# cslr_lcdc_001 register map
Vendor: Texas Instruments
Peripheral module from a debugger description file (folder C5505).
Address unit: 16 bits
Registers are 16-bit, read-write, reset 0x0 unless marked. A register's access mark holds for its fields unless they carry their own. Offsets are as the file gives them; lines under a group give offsets from that group; [hi:lo] are bit positions; {n}, {i} and the like mark numbered series; 'fields as' and 'values as' point back to an identical list; <NAME> marks a mode.

## LCDC — LCD Controller
0x00 LCDREVMIN reset 0x1000 — LCD Minor Revision Register
  [15:0] REVMIN — Minor Revision
0x02 LCDREVMAJ reset not defined — LCD Major Revision Register
  [15:0] REVMAJ — Major Revision
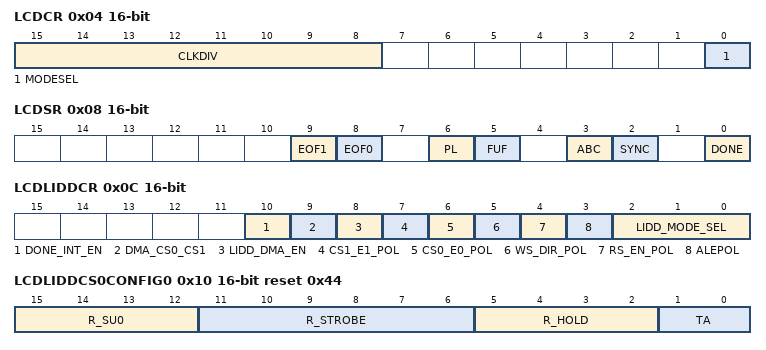
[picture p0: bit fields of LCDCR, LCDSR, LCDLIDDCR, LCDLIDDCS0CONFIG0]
0x04 LCDCR access not given — LCD Control Register
  [15:8] CLKDIV rw — Clock Divisor Value (from 0 255) is used to specify the frequency of the pixel clock (in Raster mode) or MCLK (in LIDD mode) based on the lcd_clk frequency. Pixel clock frequency can range from lcd_clk/2 to lcd_clk/255 (clkdiv=0 or clkdiv=1 are N/A); MCLK can vary from lcd_clk to lcd_clk/255 (clkdiv=0 or clkdiv=1 sets MCLK=lcd_clk)
  [0] MODESEL rw — LCD Mode Select
    0=LIDD (LCD Controller in LIDD mode); 1=RASTER (LCD Controller in Raster mode)
0x08 LCDSR access not given — LCD Status Register
  [9] EOF1 rw — End of Frame 1 0: no end of frame 1 detected 1: end of frame 1 detected
    0=CLEAR (End of frame 1 not detected); 1=SET (end of frame 1 detected)
  [8] EOF0 rw — End of Frame 0 0: no end of frame 0 detected 1: end of frame 0 detected
    0=CLEAR (End of frame 0 not detected); 1=SET (end of frame 0 detected)
  [6] PL rw — Loaded Palette 0: The palette is not loaded 1: The palette is loaded
    0=CLEAR (Palette not loaded); 1=SET (Palette loaded)
  [5] FUF rw — FIFO Underflow Status 0: FIFO has not underrun 1: LCD dither logic not supplying data to FIFO at a sufficient rate, FIFO has completely emptied and data pin driver logic has attempted to take added data from FIFO
    0=CLEAR (No FIFO underrun); 1=SET (FIFO completely empty and data pin attempted to take added data from FIFO)
  [3] ABC rw — AC Bias Count Status 0: AC bias transition counter has not decremented to zero 1: AC bias transition counter has decremented to zero, indicating that the lcd_ac_o line has transitioned the number of times which is specified by the acbi control bit-field. Counter is reloaded with value in acbi but is disabled until the user clears ABC
    0=CLEAR (AC bias transition counter not zero); 1=SET (AC bias transition counter decremented to zero)
  [2] SYNC rw — Sync Lost 0: normal 1: Frame Synchronization Lost has occurred
    0=CLEAR (Normal operation); 1=SET (Lost Frame Sync)
  [0] DONE rw — Raster or LIDD Frame Done (shared; depends on whether Raster or LIDD mode enabled) 0: Raster or DMA-to-LIDD engine is enabled 1: Raster or DMA-to-LIDD disabled and the active frame has just completed
    0=CLEAR (Raster engine enabled); 1=SET (Raster engine disabled)
0x0C LCDLIDDCR access not given — LCD LIDD Control Register
  [10] DONE_INT_EN rw — LIDD Frame Done Interrupt Enable 0: Disable LIDD Frame Done interrupt 1: Enable LIDD Frame Done interrupt (seen on LCD Status Reg bit 0)
    0=DISABLE (Disable LIDD Frame Done interrupt); 1=ENABLE (Enable LIDD Frame Done interrupt (seen on LCD Status Reg bit 0))
  [9] DMA_CS0_CS1 rw — CS0/CS1 Select for LIDD DMA writes 0: DMA writes to LIDD CS0 1: DMA writes to LIDD CS1
    0=CS0 (DMA writes to LIDD CS0); 1=CS1 (DMA writes to LIDD CS1)
  [8] LIDD_DMA_EN rw — LIDD DMA Enable 0: Deactivate DMA control of LIDD interface; DMA control is released upon completion of transfer of the currentframe of data (LIDD Frame Done) after this bit is cleared. The MPU has direct read/write access to the panel in this mode 1: Activate DMA to drive LIDD interface to support streaming data to smart panels. The MPU cannot access the panel directly in this mode
    0=DISABLE (Disable DMA control of LIDD); 1=ENABLE (Enable DMA to drive LIDD interface to support streaming data to smart panels.)
  [7] CS1_E1_POL rw — Chip Select 1/Enable 1 (Secondary) Polarity Control 0: Do Not Invert Chip Select 1/Enable 1 1: Invert Chip Select 1/Enable 1 Chip Select 1 is active low by default; Enable 1 is active high by default
    0=NORMAL (No Invert for CS1/EN1); 1=INVERT (Inverts CS1/EN1)
  [6] CS0_E0_POL rw — Chip Select 0/Enable 0 (Primary) Polarity Control 0: Do Not Invert Chip Select 0/Enable 0 1: Invert Chip Select 0/Enable 0 Chip Select 0 is active low by default; Enable 0 is active high by default
    0=NORMAL (No Invert for CS0/EN0); 1=INVERT (Inverts CS0/EN0)
  [5] WS_DIR_POL rw — Write Strobe/Direction Polarity Control 0: Do Not Invert Write Strobe/Direction 1: Invert Write Strobe/Direction Write Strobe/Direction is active low/write low by default
    0=NORMAL (No Invert for WS/Dir); 1=INVERT (Invert WS/Dir)
  [4] RS_EN_POL rw — Read Strobe/Enable Polarity Control 0: Do Not Invert Read Strobe/Enable 1: Invert Read Strobe/Enable Read Strobe is active low by default; Enable is active high by default
    0=NORMAL (No invert for RS/En); 1=INVERT (Invert RS/En)
  [3] ALEPOL rw — Address Latch Enable (ALE) Polarity Control 0: Do Not Invert ALE 1: Invert ALE ALE is active low by default
    0=NORMAL (No invert for ALE); 1=INVERT (Invert ALE)
  [2:0] LIDD_MODE_SEL rw — LIDD Mode Select. Selects type of LCD display interface for the LIDD to drive LIDD Mode Select defines the function of LCD external pins as follows ------------------------------------------------------------------------------------ PIN 000b 001b 010b 011b 100b ------------------------------------------------------------------------------------ lcd_cp En En Rs Rs N/A lcd_lp Dir Dir Ws Ws Dir lcd_fp Ale Ale Ale Ale Ale lcd_ac Cs0 Cs0 Cs0 Cs0 E0 lcd_mclk Mclk Cs1 Mclk Cs1 E1
    0=SYNC_MPU68; 1=ASYNC_MPU68; 2=SYNC_MPU80; 3=ASYNC_MPU80; 4=HITACHI (Hitachi (Async))
0x10 LCDLIDDCS0CONFIG0 reset 0x44 — LCD LIDD CS0 Configuration Register 0
  [15:12] R_SU0 — Read Strobe Set-Up cycles (lower 4 bits upper bit is in LIDD CSO config reg 1 at bit-0) Field value defines number of memclk cycles after Data Bus/Pad Output Enable, ALE, Direction bit and Chip Select 0 have been set-up before the Read Strobe is asserted when performing a read access
  [11:6] R_STROBE — Read Strobe Duration cycles Field value defines number of memclk cycles for which the Read Strobe is held active when performing a read access
  [5:2] R_HOLD — Read Strobe Hold cycles Field value defines number of memclk cycles for which Data Bus/Pad Output Enable, ALE, Direction bit and Chip Select 0 are held after the Read Strobe is deasserted when performing a read access
  [1:0] TA — Field value defines number of memclk cycles between the end of one CS0 device access and the start of another CS0 device access unless the two accesses are both reads, in which case this delay is not incurred
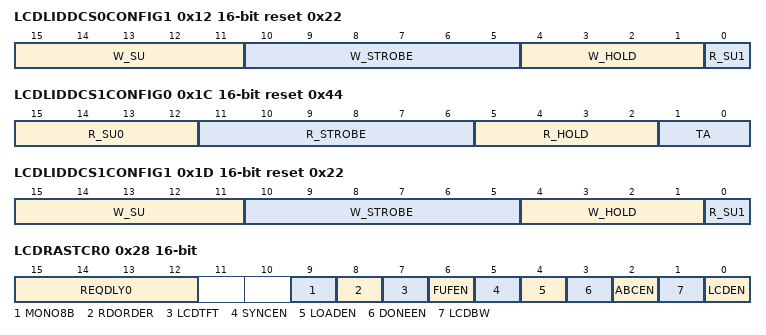
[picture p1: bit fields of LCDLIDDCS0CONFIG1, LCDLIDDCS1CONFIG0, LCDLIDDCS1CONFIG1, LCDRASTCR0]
0x12 LCDLIDDCS0CONFIG1 reset 0x22 — LCD LIDD CS0 Configuration Register 1
  [15:11] W_SU — Write Strobe Set-Up cycles Field value defines number of memclk cycles after Data Bus/Pad Output Enable, ALE, Direction bit and Chip Select 0 have been set-up before the Write Strobe is asserted when performing a write access
  [10:5] W_STROBE — Write Strobe Duration cycles Field value defines number of memclk cycles for which the Write Strobe is held active when performing a write access
  [4:1] W_HOLD — Write Strobe Hold cycles Field value defines number of memclk cycles for which Data Bus/Pad Output Enable, ALE, Direction bit and Chip Select 0 are held after the Write Strobe is deasserted when performing a write access
  [0] R_SU1 — Most Significant Bit for Read Strobe Set-Up cycles (upper bit. The lower 4 bits are located in LIDD CSO confir reg 0) Field value defines number of memclk cycles after Data Bus/Pad Output Enable, ALE, Direction bit and Chip Select 0 have been set-up before the Read Strobe is asserted when performing a read access
0x14 LCDLIDDCS0ADDR — LCD LIDD CS0 Address Read/Write Register
  [15:0] ADR_INDX — Peripheral Device Address/Index value On writes this field is loaded into the CS0 peripheral device s address generator On reads this field contains the CS0 peripheral device s status
0x18 LCDLIDDCS0DATA — LCD LIDD CS0 Data Read/Write Register
  [15:0] DATA — Peripheral Device Data value On writes this field is loaded into the CS0 peripheral device On reads this field contains the CS0 peripheral device s data
0x1C LCDLIDDCS1CONFIG0 reset 0x44 — LCD LIDD CS1 Configuration Register 0
  fields as LCDLIDDCS0CONFIG0
0x1D LCDLIDDCS1CONFIG1 reset 0x22 — LCD LIDD CS1 Configuration Register 1
  [15:11] W_SU — Write Strobe Set-Up cycles Field value defines number of memclk cycles after Data Bus/Pad Output Enable, ALE, Direction bit and Chip Select 0 have been set-up before the Write Strobe is asserted when performing a write access
  [10:5] W_STROBE — Write Strobe Duration cycles Field value defines number of memclk cycles for which the Write Strobe is held active when performing a write access
  [4:1] W_HOLD — Write Strobe Hold cycles Field value defines number of memclk cycles for which Data Bus/Pad Output Enable, ALE, Direction bit and Chip Select 0 are held after the Write Strobe is deasserted when performing a write access
  [0] R_SU1 — Read Strobe Set-Up cycles (upper bit. The lower 4 bits are located in LIDD CSO confir reg 0) Field value defines number of memclk cycles after Data Bus/Pad Output Enable, ALE, Direction bit and Chip Select 0 have been set-up before the Read Strobe is asserted when performing a read access
0x20 LCDLIDDCS1ADDR — LCD LIDD CS1 Address Read/Write Register
  fields as LCDLIDDCS0ADDR
0x24 LCDLIDDCS1DATA — LCD LIDD CS1 Data Read/Write Register
  fields as LCDLIDDCS0DATA
0x28 LCDRASTCR0 access not given — LCD Raster Control Register 0
  [15:12] REQDLY0 rw — FIFO DMA Request Delay Encoded value (0-255) used to specify the number of memory controller clocks the input FIFO DMA request should be disabled. The clock count starts after 16 words read in the input FIFO. Programming reqdly=00h disables this function
  [9] MONO8B rw — Mono 8 Bit Mode 0: lcd_pixel_o[3:0] is used to output four pixel values to the panel each pixel clock transition 1: lcd_pixel_o[7:0] is used to output eight pixel values to the panel each pixel clock transition This bit is ignored in all other modes
    0=FOUR (Each LCD pixel has 4 values); 1=EIGHT (Each LCD pixel has 8 values)
  [8] RDORDER rw — Raster Data Order Select 0: Frame buffer data is ordered from least-to-most significant bit/nibble/byte/halfword 1: Frame buffer data is ordered from most-to-least significant bit/nibble/byte/halfword
    0=CLEAR (Frame buffer data is ordered from Least to Most significant); 1=SET (Frame buffer data is ordered from Most to Least significant)
  [7] LCDTFT rw — LCD TFT 0: Passive or STN display operation enabled, dither logic is enabled 1: Active or TFT display operation enabled, external palette and DAC required, dither logic bypassed, pin timing changes to support continuous pixel clock, output enable, vsync and hsync
    0=PASSIVE (Passive display operation enabled); 1=ACTIVE (Active display operation enabled)
  [6] FUFEN rw — FIFO Underflow interrupt enable
    0=DISABLE (FIFO Interrupt Disabled); 1=ENABLE (FIFO Interrupt enabled)
  [5] SYNCEN rw — Sync Lost interrupt enable
    0=DISABLE (Sync Lost interrupt disabled); 1=ENABLE (Sync Lost interrupt enabled)
  [4] LOADEN rw — Palette Load interrupt enable
    0=DISABLE (Palette load interrupt disabled); 1=ENABLE (Palette load interrupt enabled)
  [3] DONEEN rw — Frame Done interrupt enable
    0=DISABLE (Frame done interrupt disabled); 1=ENABLE (Frame done interrupt enabled)
  [2] ABCEN rw — AC Bias Count interrupt enable
    0=DISABLE (AC bias count interrupt disabled); 1=ENABLE (AC bias count interrupt enabled)
  [1] LCDBW rw — LCD Monochrome 0: Color operation enabled 1: Monochrome operation enabled
    0=COLOR (Color enabled); 1=MONO (Monochrome enabled)
  [0] LCDEN rw — LCD Controller Enable
    0=DISABLE (LCD controller disabled); 1=ENABLE (LCD controller enabled)
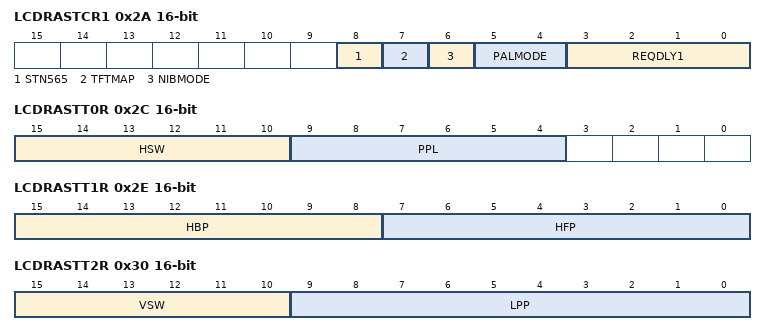
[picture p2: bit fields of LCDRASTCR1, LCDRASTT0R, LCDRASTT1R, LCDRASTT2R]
0x2A LCDRASTCR1 access not given — LCD Raster Control Register 1
  [8] STN565 rw — 12 BPP (5-6-5) mode 0: off 1: on (16 bit data in frame buffer, but only 12 bits are dithered and sent out)
    0=OFF (12 BPP mode off); 1=ON (12 BPP mode on)
  [7] TFTMAP rw — TFT Alternate Signal Mapping 0: output pixel data for 1, 2, 4, and 8 bpp modes will be right aligned on lcd_pins (11:0) 1: output pixel data for 1, 2, 4, and 8 bpp will be converted to 5,6,5 format and use pins (15:0) R3 R2 R1 R0 R3 G3 G2 G1 G0 G3 G2 B3 B2 B1 B0 B3
    0=CLEAR (output pixel data for 1, 2, 4, and 8 bpp modes will be right aligned on lcd_pins (11:0)); 1=SET (output pixel data for 1, 2, 4, and 8 bpp will be converted to 5,6,5 format and use pins (15:0) R3 R2 R1 R0 R3 G3 G2 G1 G0 G3 G2 B3 B2 B1 B0 B3)
  [6] NIBMODE rw — Nibble Mode 0: Nibble mode is disabled 1: Nibble mode is enabled
    0=DISABLE (Nibble mode disabled); 1=ENABLE (Nibble mode enabled)
  [5:4] PALMODE rw — Palette Loading Mode 00: Palette and data loading ( reset value) 01: Palette loading 10: Data loading
    0=DEFAULT (Palette and data loading (default)); 1=PALETTE (Palette loading); 2=DATA (Data loading)
  [3:0] REQDLY1 rw — FIFO DMA Request Delay Encoded value (0-255) used to specify the number of memory controller clocks the input FIFO DMA request should be disabled. The clock count starts after 16 words read in the input FIFO. Programming reqdly=00h disables this function
0x2C LCDRASTT0R access not given — LCD Raster Timing 0 Register
  [15:10] HSW rw — Horizontal Sync Pulse Width Encoded value (from 1 64) is used to specify number of pixel clock periods to pulse the line clock at the end of each line (program to value minus one). Note that pixel clock is held in its inactive state during the generation of the line clock in passive display mode and is permitted to transition in active display mode
  [9:4] PPL rw — Pixels-per-line Encoded value (from 1 1024) is used to specify number of pixels contained within each line on the LCD display (program to value minus one)
0x2E LCDRASTT1R — LCD Raster Timing 1 Register
  [15:8] HBP — Horizontal Back Porch Encoded value (from 1 256) is used to specify number of pixel clock periods to add to the beginning of a line transmission before the first set of pixels is output to the display (program to value minus one). Note that pixel clock is held in its inactive state during the beginning of line wait period in passive display mode and is permitted to transition in active display mode
  [7:0] HFP — Horizontal Front Porch Encoded value (from 1 256) is used to specify number of pixel clock periods to add to the end of a line transmission before line clock is asserted (program to value minus one). Note that pixel clock is held in its inactive state during the end of line wait period in passive display mode and is permitted to transition in active display mode
0x30 LCDRASTT2R — LCD Raster Timing 2 Register
  [15:10] VSW — Vertical Sync Pulse Width In active mode (lcdtft=1), encoded value (from 1 64) used to specify number of line clock periods to pulse the lcd_fp pin at the end of each frame after the end of frame wait (vfp) period elapses. Frame clock used as VSYNC signal in active mode In passive mode (lcdtft=0), encoded value (from 1 64) used to specify number of extra line clock periods to insert after the vertical front porch (vfp) period has elapsed. Note that the width of lcd_fp is not effected by vsw in passive mode, and that line clock transitions during the insertionof the extra line clock periods (program to value minus one)
  [9:0] LPP — Pixels-per-line Encoded value (from 1 1024) used to specify number of lines per panel. It represents the total number of lines on the LCD (program to value minus one)
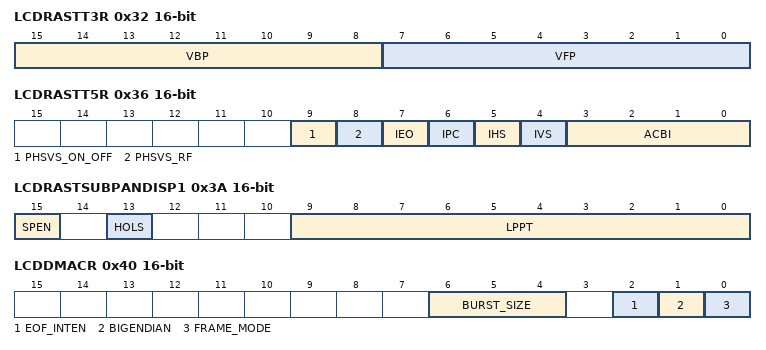
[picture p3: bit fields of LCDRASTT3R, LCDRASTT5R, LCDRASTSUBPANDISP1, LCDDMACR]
0x32 LCDRASTT3R — LCD Raster Timing 3 Register
  [15:8] VBP — Vertical Back Porch Value (from 0 255) used to specify number of line clock periods to add to the beginning of a frame before the first set of pixels is output to the display. Note that line clock transitions during the insertion of the extra line clock periods
  [7:0] VFP — Vertical Front Porch Value (from 0 255) used to specify number of line clock periods to add to the end of each frame. Note that the line clock transitions during the insertion of the extra line clock periods
0x34 LCDRASTT4R access not given — LCD Raster Timing 4 Register
  [15:8] ACB rw — AC Bias Pin Frequency Value (from 0 255) used to specify the number of line clocks to count before transitioning the AC Bias pin. This pin is used to periodically invert the polarity of the power supply to prevent DC charge build-up within the display. acb: Number of line clocks/toggle of the lcd_ac pin
0x36 LCDRASTT5R access not given — LCD Raster Timing 5 Register
  [9] PHSVS_ON_OFF rw — Hsync/Vsync Pixel Clock Control On/Off Should be ON only when in TFT mode 0: lcd_lp and lcd_fp are driven on opposite edges of pixel clock than the lcd_pixel_o 1: lcd_lp and lcd_fp are driven according to bit 24
    0=CLEAR (lcd_lp and lcd_fp are driven on opposite edges of pixel clock than the lcd_pixel_o); 1=SET (lcd_lp and lcd_fp are driven according to bit 24)
  [8] PHSVS_RF rw — Program Hsync/Vsync Rise or Fall 0: lcd_lp and lcd_fp are driven on rising edge of pixel clock. (bit 25 must be set to 1) 1: lcd_lp and lcd_fp are driven on falling edge of pixel clock. (bit 25 must be set to 1)
    0=RISING (lcd_lp and lcd_fp are driven on rising edge of pixel clock. (bit 25 must be set to 1)); 1=FALLING (lcd_lp and lcd_fp are driven on falling edge of pixel clock. (bit 25 must be set to 1))
  [7] IEO rw — Invert Output Enable 0: lcd_ac pin is active high in active display mode 1: lcd_ac pin is active low in active display mode Active display mode: data driven out to the LCD s data lines on programmed pixel clock edge when AC-bias is active. Note that IEO is ignored in passive display mode
    0=HIGH (LCD_AC pin is active high in Active Display mode); 1=LOW (LCD_AC pin is active low in Active Display mode)
  [6] IPC rw — Invert Pixel Clock 0: Data is driven on the LCD s data lines on the rising edge of lcd_cp 1: Data is driven on the LCD s data lines on the falling edge of lcd_cp
    0=RISING (Data driven on rising edge); 1=FALLING (Data driven on Falling edge)
  [5] IHS rw — Invert Hsync 0: lcd_lp pin is active high and inactive low 1: lcd_lp pin is active low and inactive high Active and passive mode: horizontal sync pulse/line clock active between lines, after end of line wait period
    0=CLEAR (lcd_lp pin is active high and inactive low); 1=SET (lcd_lp pin is active low and inactive high)
  [4] IVS rw — Invert Vsync 0: lcd_fp pin is active high and inactive low 1: lcd_fp pin is active low and inactive high Active mode: vertical sync pulse active between frames, after end of frame wait period Passive mode: frame clock active during first line of each frame
    0=CLEAR (lcd_fp pin is active high and inactive low); 1=SET (lcd_fp pin is active low and inactive high)
  [3:0] ACBI rw — AC Bias Pin Transitions per Interrupt Value (from 0 to 255) used to specify the number of AC Bias pin transitions to count before setting the line count status (lcs) bit, signaling an interrupt request. Counter is frozen when lcs is set and is restarted when lcs is cleared by software. This function is disabled when acbi = 0x0000
0x38 LCDRASTSUBPANDISP0 access not given — LCD Raster Sub-panel Display Register 0
  [15:4] DPD rw — Default Pixel Data DPD defines the default value of the pixel data sent to the panel for the lines until LPPT is reached or after passing the LPPT
0x3A LCDRASTSUBPANDISP1 access not given — LCD Raster Sub-panel Display Register 1
  [15] SPEN rw — Sub panel Enable 0: function disabled 1: sub-panel function mode enabled
    0=DISABLE (Sub panel function disabled); 1=ENABLE (Sub panel function enabled)
  [13] HOLS rw — High or Low Signal The field indicates the position of sub-panel compared to the LPPT value
    0=LOW (subpanel below LPPT value); 1=HIGH (subpanel above LPPT value)
  [9:0] LPPT rw — Line Per Panel Threshold This field defines the number of lines to be refreshed (1 1024)
0x40 LCDDMACR access not given — LCD DMA Control Register
  [6:4] BURST_SIZE rw — Burst Size setting for DMA transfers (all DMA transfers are 32 bits wide)
    0=BSIZE1 (burst size of 1); 1=BSIZE2 (burst size of 2); 2=BSIZE4 (burst size of 4); 3=BSIZE8 (burst size of 8); 4=BSIZE16 (burst size of 16)
  [2] EOF_INTEN rw — End of Frame interrupt enable Setting this bit allows the End of Frame 0 or 1 Status bits in the LCD Status Register to trigger an interrupt 0: End of Frame 0/1Interrupt disabled 1: End of Frame 0/1Interrupt enabled
    0=DISABLED (EoF Interrupt disabled); 1=ENABLED (EoF Interrupt enabled)
  [1] BIGENDIAN rw — Big Endian enable Use this bit when the processor is operating in Big Endian mode and writes to the frame buffer(s) are less than 32 bits wide; only in this scenario we need to change the byte alignment for data coming into the FIFO from the frame buffer(s) 0: Big Endian data reordering disabled 1: Big Endian data reordering enabled
    0=DISABLED (Big Endian disabled); 1=ENABLED (Big Endian enabled)
  [0] FRAME_MODE rw — Frame Mode 0: one frame buffer (FB0 only) used 1: two frame buffers used; DMA ping-pongs between FB0 and FB1 in this mode
    0=ONE (One Frame buffer used); 1=TWO (two frame buffers used.)
0x44 LCDDMAFB0BAR0 — LCD DMA Frame Buffer 0 Base Address Register 0
  [15:0] FB0_BASE0 — Frame Buffer 0 Base Address pointer LSW; 2 LSBs are hardwired to be 00
0x46 LCDDMAFB0BAR1 — LCD DMA Frame Buffer 0 Base Address Register 1
  [15:0] FB0_BASE1 — Frame Buffer 0 Base Address pointer MSW
0x48 LCDDMAFB0CAR0 — LCD DMA Frame Buffer 0 Ceiling Address Register 0
  [15:0] FB0_CEIL0 — Frame Buffer 0 Ceiling Address pointer LSW; 2 LSBs are hardwired to be 00
0x49 LCDDMAFB0CAR1 — LCD DMA Frame Buffer 0 Ceiling Address Register 1
  [15:0] FB0_CEIL1 — Frame Buffer 0 Ceiling Address pointer MSW
0x4C LCDDMAFB1BAR0 — LCD DMA Frame Buffer 1 Base Address Register 0
  [15:0] FB1_BASE0 — Frame Buffer 1 Base Address pointer LSW; 2 LSBs are hardwired to be 00
0x4D LCDDMAFB1BAR1 — LCD DMA Frame Buffer 1 Base Address Register 1
  [15:0] FB1_BASE1 — Frame Buffer 1 Base Address pointer MSW
0x50 LCDDMAFB1CAR0 — LCD DMA Frame Buffer 1 Ceiling Address Register 0
  [15:0] FB1_CEIL0 — Frame Buffer 1 Ceiling Address pointer LSW; 2 LSBs are hardwired to be 00
0x51 LCDDMAFB1CAR1 — LCD DMA Frame Buffer 1 Ceiling Address Register 1
  [15:0] FB1_CEIL1 — Frame Buffer 1 Ceiling Address pointer MSW
